AUTOSAR XML (schema 4-2-1)
package /RootP_ASWC_M41B
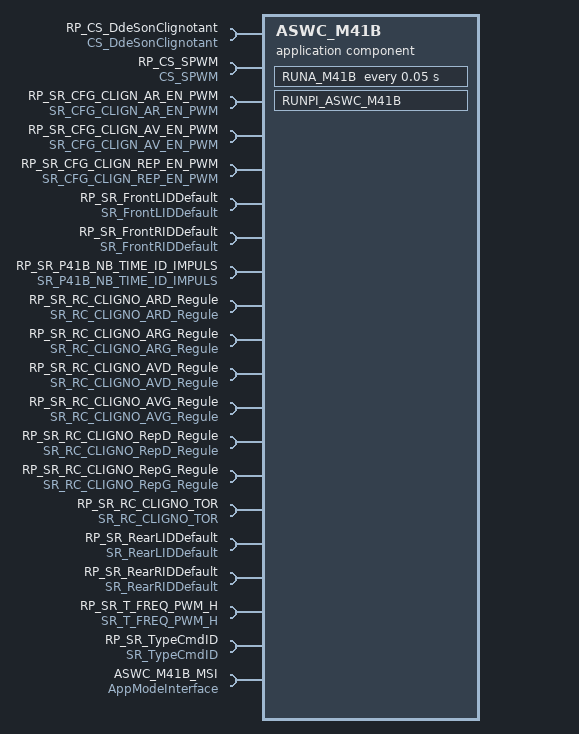
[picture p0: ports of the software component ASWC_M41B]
  application sw component type ASWC_M41B
    9 x provide/require port:
      PRP_SR_CmdFrontLID: nonqueued-receiver-com-spec{data-element=CmdFrontLID, enable-update=0, handle-data-status=1, handle-never-received=0, init-value=CONST_tLOG_0:0}, provided-required-interface=SR_CmdFrontLID
      PRP_SR_CmdFrontRID: nonqueued-receiver-com-spec{data-element=CmdFrontRID, enable-update=0, handle-data-status=1, handle-never-received=0, init-value=CONST_tLOG_0:0}, provided-required-interface=SR_CmdFrontRID
      PRP_SR_CmdReapeterLID: nonqueued-receiver-com-spec{data-element=CmdReapeterLID, enable-update=0, handle-data-status=1, handle-never-received=0, init-value=CONST_tLOG_0:0}, provided-required-interface=SR_CmdReapeterLID
      PRP_SR_CmdReapeterRID: nonqueued-receiver-com-spec{data-element=CmdReapeterRID, enable-update=0, handle-data-status=1, handle-never-received=0, init-value=CONST_tLOG_0:0}, provided-required-interface=SR_CmdReapeterRID
      PRP_SR_CmdRearLID: nonqueued-receiver-com-spec{data-element=CmdRearLID, enable-update=0, handle-data-status=1, handle-never-received=0, init-value=CONST_tLOG_0:0}, provided-required-interface=SR_CmdRearLID
      PRP_SR_CmdRearRID: nonqueued-receiver-com-spec{data-element=CmdRearRID, enable-update=0, handle-data-status=1, handle-never-received=0, init-value=CONST_tLOG_0:0}, provided-required-interface=SR_CmdRearRID
      PRP_SR_IndicatorLightLeft: nonqueued-receiver-com-spec{data-element=IndicatorLightLeft, enable-update=0, handle-data-status=1, handle-never-received=0, init-value=CONST_tLOG_0:0}, provided-required-interface=SR_IndicatorLightLeft
      PRP_SR_IndicatorLightRight: nonqueued-receiver-com-spec{data-element=IndicatorLightRight, enable-update=0, handle-data-status=1, handle-never-received=0, init-value=CONST_tLOG_0:0}, provided-required-interface=SR_IndicatorLightRight
      PRP_SR_InfoStateID: provided-required-interface=SR_InfoStateID
        required-com-specs:
          data-element=FlagImpulsEnd, enable-update=0, handle-data-status=1, handle-never-received=0, init-value=CONST_tLOG_0:0
          data-element=StateID, enable-update=0, handle-data-status=1, handle-never-received=0, init-value=CONST_tLOG_0:0
    20 x require port:
      RP_CS_DdeSonClignotant: required-interface=CS_DdeSonClignotant
      RP_CS_SPWM: required-interface=CS_SPWM
      RP_SR_CFG_CLIGN_AR_EN_PWM: nonqueued-receiver-com-spec{data-element=CFG_CLIGN_AR_EN_PWM, enable-update=0, handle-data-status=1, handle-never-received=0, init-value=CONST_tBYTE_1:1}, required-interface=SR_CFG_CLIGN_AR_EN_PWM
      RP_SR_CFG_CLIGN_AV_EN_PWM: nonqueued-receiver-com-spec{data-element=CFG_CLIGN_AV_EN_PWM, enable-update=0, handle-data-status=1, handle-never-received=0, init-value=CONST_tBYTE_1:1}, required-interface=SR_CFG_CLIGN_AV_EN_PWM
      RP_SR_CFG_CLIGN_REP_EN_PWM: nonqueued-receiver-com-spec{data-element=CFG_CLIGN_REP_EN_PWM, enable-update=0, handle-data-status=1, handle-never-received=0, init-value=CONST_tBYTE_1:1}, required-interface=SR_CFG_CLIGN_REP_EN_PWM
      RP_SR_FrontLIDDefault: nonqueued-receiver-com-spec{data-element=FrontLIDDefault, enable-update=0, handle-data-status=1, handle-never-received=0, init-value=CONST_tLOG_0:0}, required-interface=SR_FrontLIDDefault
      RP_SR_FrontRIDDefault: nonqueued-receiver-com-spec{data-element=FrontRIDDefault, enable-update=0, handle-data-status=1, handle-never-received=0, init-value=CONST_tLOG_0:0}, required-interface=SR_FrontRIDDefault
      RP_SR_P41B_NB_TIME_ID_IMPULS: nonqueued-receiver-com-spec{data-element=P41B_NB_TIME_ID_IMPULS, enable-update=0, handle-data-status=1, handle-never-received=0, init-value=CONST_tBYTE_3:3}, required-interface=SR_P41B_NB_TIME_ID_IMPULS
      RP_SR_RC_CLIGNO_ARD_Regule: nonqueued-receiver-com-spec{data-element=RC_CLIGNO_ARD_Regule, enable-update=0, handle-data-status=1, handle-never-received=0, init-value=CONST_tWORD_100:100}, required-interface=SR_RC_CLIGNO_ARD_Regule
      RP_SR_RC_CLIGNO_ARG_Regule: nonqueued-receiver-com-spec{data-element=RC_CLIGNO_ARG_Regule, enable-update=0, handle-data-status=1, handle-never-received=0, init-value=CONST_tWORD_100:100}, required-interface=SR_RC_CLIGNO_ARG_Regule
      RP_SR_RC_CLIGNO_AVD_Regule: nonqueued-receiver-com-spec{data-element=RC_CLIGNO_AVD_Regule, enable-update=0, handle-data-status=1, handle-never-received=0, init-value=CONST_tWORD_100:100}, required-interface=SR_RC_CLIGNO_AVD_Regule
      RP_SR_RC_CLIGNO_AVG_Regule: nonqueued-receiver-com-spec{data-element=RC_CLIGNO_AVG_Regule, enable-update=0, handle-data-status=1, handle-never-received=0, init-value=CONST_tWORD_100:100}, required-interface=SR_RC_CLIGNO_AVG_Regule
      RP_SR_RC_CLIGNO_RepD_Regule: nonqueued-receiver-com-spec{data-element=RC_CLIGNO_RepD_Regule, enable-update=0, handle-data-status=1, handle-never-received=0, init-value=CONST_tWORD_100:100}, required-interface=SR_RC_CLIGNO_RepD_Regule
      RP_SR_RC_CLIGNO_RepG_Regule: nonqueued-receiver-com-spec{data-element=RC_CLIGNO_RepG_Regule, enable-update=0, handle-data-status=1, handle-never-received=0, init-value=CONST_tWORD_100:100}, required-interface=SR_RC_CLIGNO_RepG_Regule
      RP_SR_RC_CLIGNO_TOR: nonqueued-receiver-com-spec{data-element=RC_CLIGNO_TOR, enable-update=0, handle-data-status=1, handle-never-received=0, init-value=CONST_tWORD_255:255}, required-interface=SR_RC_CLIGNO_TOR
      RP_SR_RearLIDDefault: nonqueued-receiver-com-spec{data-element=RearLIDDefault, enable-update=0, handle-data-status=1, handle-never-received=0, init-value=CONST_tLOG_0:0}, required-interface=SR_RearLIDDefault
      RP_SR_RearRIDDefault: nonqueued-receiver-com-spec{data-element=RearRIDDefault, enable-update=0, handle-data-status=1, handle-never-received=0, init-value=CONST_tLOG_0:0}, required-interface=SR_RearRIDDefault
      RP_SR_T_FREQ_PWM_H: nonqueued-receiver-com-spec{data-element=T_FREQ_PWM_H, enable-update=0, handle-data-status=1, handle-never-received=0, init-value=CONST_tWORD_7:7}, required-interface=SR_T_FREQ_PWM_H
      RP_SR_TypeCmdID: nonqueued-receiver-com-spec{data-element=TypeCmdID, enable-update=0, handle-data-status=1, handle-never-received=0, init-value=CONST_t_TypeCmdID_0:0}, required-interface=SR_TypeCmdID
      ASWC_M41B_MSI: required-interface=AppModeInterface
    behavior IB_ASWC_M41B: data-type-mapping=ApplicationModeMapping, handle-termination-and-restart=NO-SUPPORT
      ar-typed-per-instance-memorys:
        5 x data:
          PIM_M41B_ClignoDPrec: type=tLOG, init-value=CONST_tLOG_0:0
          PIM_M41B_ClignoGPrec: type=tLOG, init-value=CONST_tLOG_0:0
          PIM_M41B_CounterFreeRunning: type=tDWORD, init-value=CONST_tDWORD_0:0
          PIM_M41B_CountImpuls: type=tBYTE, init-value=CONST_tBYTE_0:0
          PIM_M41B_TypeCmdIDPrec: type=t_TypeCmdID, init-value=CONST_PIM_M41B_TypeCmdIDPrec_t_TypeCmdID_cNoCmdID:0
      timing event RUNA_M41B_Cyclic: start-on-event=RUNA_M41B, period=0.05
        disabled-mode:
          ASWC_M41B_MSI.AppMode.APP_WAKEUP
          ASWC_M41B_MSI.AppMode.APP_OFF
          ASWC_M41B_MSI.AppMode.APP_SYNC_INIT
          ASWC_M41B_MSI.AppMode.APP_CONFIG
      swc mode switch event RUNPI_ASWC_M41B_ENTRY: start-on-event=RUNPI_ASWC_M41B, activation=ON-ENTRY, mode=ASWC_M41B_MSI.AppMode.APP_WAKEUP
      runnable RUNA_M41B
        data-read-access:
          27 x access:
            dra_RP_SR_FrontLIDDefault_FrontLIDDefault: accessed-variable=RP_SR_FrontLIDDefault.FrontLIDDefault
            dra_RP_SR_FrontRIDDefault_FrontRIDDefault: accessed-variable=RP_SR_FrontRIDDefault.FrontRIDDefault
            dra_RP_SR_RearLIDDefault_RearLIDDefault: accessed-variable=RP_SR_RearLIDDefault.RearLIDDefault
            dra_RP_SR_RearRIDDefault_RearRIDDefault: accessed-variable=RP_SR_RearRIDDefault.RearRIDDefault
            dra_RP_SR_TypeCmdID_TypeCmdID: accessed-variable=RP_SR_TypeCmdID.TypeCmdID
            dra_RP_SR_CFG_CLIGN_AR_EN_PWM_CFG_CLIGN_AR_EN_PWM: accessed-variable=RP_SR_CFG_CLIGN_AR_EN_PWM.CFG_CLIGN_AR_EN_PWM
            dra_RP_SR_CFG_CLIGN_AV_EN_PWM_CFG_CLIGN_AV_EN_PWM: accessed-variable=RP_SR_CFG_CLIGN_AV_EN_PWM.CFG_CLIGN_AV_EN_PWM
            dra_RP_SR_CFG_CLIGN_REP_EN_PWM_CFG_CLIGN_REP_EN_PWM: accessed-variable=RP_SR_CFG_CLIGN_REP_EN_PWM.CFG_CLIGN_REP_EN_PWM
            dra_RP_SR_P41B_NB_TIME_ID_IMPULS_P41B_NB_TIME_ID_IMPULS: accessed-variable=RP_SR_P41B_NB_TIME_ID_IMPULS.P41B_NB_TIME_ID_IMPULS
            dra_RP_SR_RC_CLIGNO_ARD_Regule_RC_CLIGNO_ARD_Regule: accessed-variable=RP_SR_RC_CLIGNO_ARD_Regule.RC_CLIGNO_ARD_Regule
            dra_RP_SR_RC_CLIGNO_ARG_Regule_RC_CLIGNO_ARG_Regule: accessed-variable=RP_SR_RC_CLIGNO_ARG_Regule.RC_CLIGNO_ARG_Regule
            dra_RP_SR_RC_CLIGNO_AVD_Regule_RC_CLIGNO_AVD_Regule: accessed-variable=RP_SR_RC_CLIGNO_AVD_Regule.RC_CLIGNO_AVD_Regule
            dra_RP_SR_RC_CLIGNO_AVG_Regule_RC_CLIGNO_AVG_Regule: accessed-variable=RP_SR_RC_CLIGNO_AVG_Regule.RC_CLIGNO_AVG_Regule
            dra_RP_SR_RC_CLIGNO_RepD_Regule_RC_CLIGNO_RepD_Regule: accessed-variable=RP_SR_RC_CLIGNO_RepD_Regule.RC_CLIGNO_RepD_Regule
            dra_RP_SR_RC_CLIGNO_RepG_Regule_RC_CLIGNO_RepG_Regule: accessed-variable=RP_SR_RC_CLIGNO_RepG_Regule.RC_CLIGNO_RepG_Regule
            dra_RP_SR_RC_CLIGNO_TOR_RC_CLIGNO_TOR: accessed-variable=RP_SR_RC_CLIGNO_TOR.RC_CLIGNO_TOR
            dra_RP_SR_T_FREQ_PWM_H_T_FREQ_PWM_H: accessed-variable=RP_SR_T_FREQ_PWM_H.T_FREQ_PWM_H
            dra_PRP_SR_CmdFrontLID_CmdFrontLID: accessed-variable=PRP_SR_CmdFrontLID.CmdFrontLID
            dra_PRP_SR_CmdFrontRID_CmdFrontRID: accessed-variable=PRP_SR_CmdFrontRID.CmdFrontRID
            dra_PRP_SR_CmdReapeterLID_CmdReapeterLID: accessed-variable=PRP_SR_CmdReapeterLID.CmdReapeterLID
            dra_PRP_SR_CmdReapeterRID_CmdReapeterRID: accessed-variable=PRP_SR_CmdReapeterRID.CmdReapeterRID
            dra_PRP_SR_CmdRearLID_CmdRearLID: accessed-variable=PRP_SR_CmdRearLID.CmdRearLID
            dra_PRP_SR_CmdRearRID_CmdRearRID: accessed-variable=PRP_SR_CmdRearRID.CmdRearRID
            dra_PRP_SR_InfoStateID_FlagImpulsEnd: accessed-variable=PRP_SR_InfoStateID.FlagImpulsEnd
            dra_PRP_SR_IndicatorLightLeft_IndicatorLightLeft: accessed-variable=PRP_SR_IndicatorLightLeft.IndicatorLightLeft
            dra_PRP_SR_IndicatorLightRight_IndicatorLightRight: accessed-variable=PRP_SR_IndicatorLightRight.IndicatorLightRight
            dra_PRP_SR_InfoStateID_StateID: accessed-variable=PRP_SR_InfoStateID.StateID
        data-write-access:
          10 x access:
            dwa_PRP_SR_CmdFrontLID_CmdFrontLID: accessed-variable=PRP_SR_CmdFrontLID.CmdFrontLID
            dwa_PRP_SR_CmdFrontRID_CmdFrontRID: accessed-variable=PRP_SR_CmdFrontRID.CmdFrontRID
            dwa_PRP_SR_CmdReapeterLID_CmdReapeterLID: accessed-variable=PRP_SR_CmdReapeterLID.CmdReapeterLID
            dwa_PRP_SR_CmdReapeterRID_CmdReapeterRID: accessed-variable=PRP_SR_CmdReapeterRID.CmdReapeterRID
            dwa_PRP_SR_CmdRearLID_CmdRearLID: accessed-variable=PRP_SR_CmdRearLID.CmdRearLID
            dwa_PRP_SR_CmdRearRID_CmdRearRID: accessed-variable=PRP_SR_CmdRearRID.CmdRearRID
            dwa_PRP_SR_InfoStateID_FlagImpulsEnd: accessed-variable=PRP_SR_InfoStateID.FlagImpulsEnd
            dwa_PRP_SR_IndicatorLightLeft_IndicatorLightLeft: accessed-variable=PRP_SR_IndicatorLightLeft.IndicatorLightLeft
            dwa_PRP_SR_IndicatorLightRight_IndicatorLightRight: accessed-variable=PRP_SR_IndicatorLightRight.IndicatorLightRight
            dwa_PRP_SR_InfoStateID_StateID: accessed-variable=PRP_SR_InfoStateID.StateID
        sync call sscp_RUNA_M41B_CS_DdeSonClignotant_Cmd: operation=RP_CS_DdeSonClignotant.Cmd, timeout=0
        sync call sscp_RUNA_M41B_CS_SPWM_Set: operation=RP_CS_SPWM.Set, timeout=0
      runnable RUNPI_ASWC_M41B
package /RootP_Implementatation
  swc implementation Implementatation_ASWC_M41B: programming-language=C, sw-version=1.0.0, vendor-id=1, behavior=IB_ASWC_M41B
    code-descriptors:
      code SRC: artifact-descriptors=autosar-engineering-object={short-label=EngObject, category=SWSRC}
    resource consumption Resources
